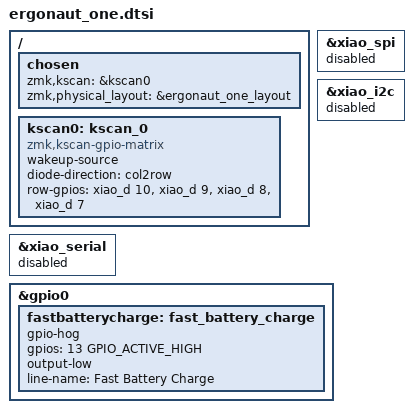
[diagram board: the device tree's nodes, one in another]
#include "ergonaut_one_layout.dtsi"

/ {
    chosen {
        zmk,kscan = &kscan0;
        zmk,physical_layout = &ergonaut_one_layout;
    };

    kscan0: kscan_0 {
        compatible = "zmk,kscan-gpio-matrix";
        wakeup-source;
        diode-direction = "col2row";
        row-gpios = <&xiao_d 10 (GPIO_ACTIVE_HIGH | GPIO_PULL_DOWN)>,
                    <&xiao_d 9 (GPIO_ACTIVE_HIGH | GPIO_PULL_DOWN)>,
                    <&xiao_d 8 (GPIO_ACTIVE_HIGH | GPIO_PULL_DOWN)>,
                    <&xiao_d 7 (GPIO_ACTIVE_HIGH | GPIO_PULL_DOWN)>;
    };
};

&xiao_spi { status = "disabled"; };
&xiao_i2c { status = "disabled"; };
&xiao_serial { status = "disabled"; };

&gpio0 {
    fastbatterycharge: fast_battery_charge {
        gpio-hog;
        gpios = <13 GPIO_ACTIVE_HIGH>;
        output-low;
        line-name = "Fast Battery Charge";
    };
};
